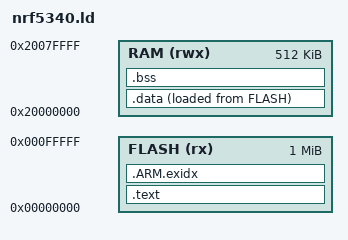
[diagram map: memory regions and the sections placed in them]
/* The DK's nRF5340 application core, whole flash and RAM, from address 0 (no bootloader). */
MEMORY
{
    FLASH (rx)  : ORIGIN = 0x00000000, LENGTH = 1024K
    RAM   (rwx) : ORIGIN = 0x20000000, LENGTH = 512K
}

ENTRY(Reset_Handler)

SECTIONS
{
    .text :
    {
        KEEP(*(.vectors))
        *(.text*)
        *(.rodata*)
        . = ALIGN(4);
    } > FLASH

    .ARM.exidx : { *(.ARM.exidx*) } > FLASH

    .data :
    {
        __data_start = .;
        *(.data*)
        . = ALIGN(4);
        __data_end = .;
    } > RAM AT > FLASH
    __data_load = LOADADDR(.data);

    .bss (NOLOAD) :
    {
        __bss_start = .;
        *(.bss*)
        *(COMMON)
        . = ALIGN(4);
        __bss_end = .;
    } > RAM

    __stack_top = ORIGIN(RAM) + LENGTH(RAM);
}
